# PIC32MX174F256B device description
Architecture: MIPS; Family: PIC32MX; Series: PIC32MX
Registers are 32-bit, read-write, no defined reset value unless marked. A register's access mark holds for its fields unless they carry their own. Offsets are from the block's base; [hi:lo] are bit positions; {n}, {i} and the like mark numbered series; 'fields as' and 'values as' point back to an identical list.

## OSC
Instances: OSC 0x1f80f000 in periph1
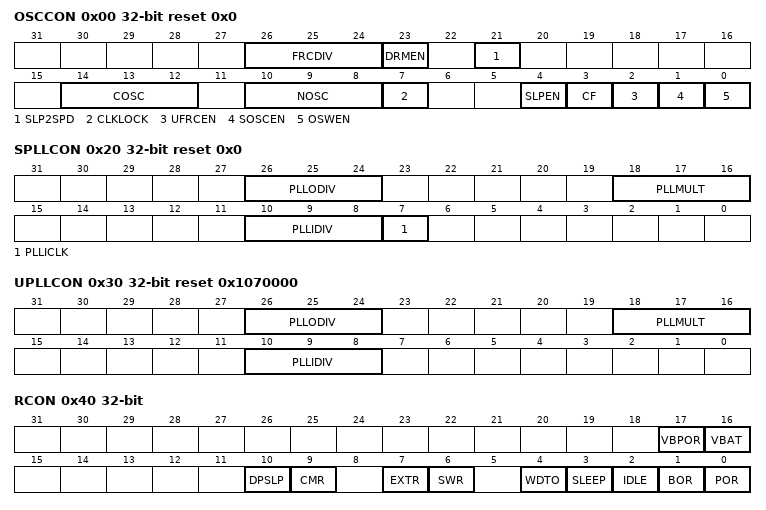
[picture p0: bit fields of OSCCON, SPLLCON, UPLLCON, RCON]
0x00 OSCCON reset 0x0 — Oscillator Control Register
  [26:24] FRCDIV — Internal Fast RC Oscillator Clock Divider bits
    7=DIV_256 (FRC divided by 256); 6=DIV_64 (FRC divided by 64); 5=DIV_32 (FRC divided by 32); 4=DIV_16 (FRC divided by 16); 3=DIV_8 (FRC divided by 8); 2=DIV_4 (FRC divided by 4); 1=DIV_2 (FRC divided by 2); 0=DIV_1 (FRC divided by 1 (default setting))
  [23] DRMEN — Dream Mode Enable bit
    1=ENABLE (Dream mode is enabled); 0=DISABLE (Dream mode is disabled)
  [21] SLP2SPD — Sleep Two-speed Start-up Control bit
    1=FRC (Use FRC as SYSCLK until the selected clock is ready); 0=DIRECT (Use the selected clock directly)
  [14:12] COSC — Current Oscillator Selection bits
    5=LPRC (Internal Low-Power RC (LPRC) Oscillator); 4=SOSC (Secondary Oscillator (SOSC)); 2=POSC (Primary Oscillator (POSC) (HS or EC)); 1=SPLL (System PLL (SPLL)); 0=FRC (Internal Fast RC (FRC) Oscillator divided by FRCDIV bits (FRCDIV))
  [10:8] NOSC — New Oscillator Selection bits
    values as COSC
  [7] CLKLOCK — Clock Selection Lock Enable bit
    1=ON (Clock and PLL selections are locked); 0=OFF (Clock and PLL selections are not locked and may be modified)
  [4] SLPEN — Sleep Mode Enable bit
    1=ENABLE (Device will enter Sleep mode when a WAIT instruction is executed); 0=DISABLE (Device will enter Idle mode when a WAIT instruction is executed)
  [3] CF — Clock Fail Detect bit
    1=DET (FSCM has detected a clock failure); 0=NO_DET (No clock failure has been detected)
  [2] UFRCEN — USB FRC Clock Enable bit
    1=FRC_EN (Enable FRC as the USB clock source); 0=FRC_DIS (Use the Primary Oscillator or UPLL as the USB clock source)
  [1] SOSCEN — Secondary Oscillator Enable bit
    1=ON (Enable Secondary Oscillator); 0=OFF (Disable Secondary Oscillator)
  [0] OSWEN — Oscillator Switch Enable bit
    1=ON (Initiate an oscillator switch to selection specified by NOSC bits); 0=OFF (Oscillator switch is complete)
0x10 OSCTUN reset 0x0 — FRC Tuning Register
  [5:0] TUN — FRC Oscillator Tuning bits
    32=FREQ_MIN (Center frequency -2%); 0=FREQ_CTR (Center frequency; Oscillator runs at nominal frequency (8 MHz)); 31=FREQ_MAX (Center frequency +2%)
0x20 SPLLCON reset 0x0 — System PLL Control Register
  [26:24] PLLODIV — System PLL Output Clock Divider bits
    7=DIV_256 (PLL Divide by 256); 6=DIV_64 (PLL Divide by 64); 5=DIV_32 (PLL Divide by 32); 4=DIV_16 (PLL Divide by 16); 3=DIV_8 (PLL Divide by 8); 2=DIV_4 (PLL Divide by 4); 1=DIV_2 (PLL Divide by 2); 0=DIV_1 (PLL Divide by 1)
  [18:16] PLLMULT — System PLL Multiplier bits
    7=MUL_24 (Multiply by 24); {v}=MUL_{v+15} (Multiply by {v+15}) (v=0..6)
  [10:8] PLLIDIV — System PLL Input Clock Divider bits
    7=DIV_12 (Divide by 12); 6=DIV_10 (Divide by 10); {v}=DIV_{v+1} (Divide by {v+1}) (v=0..5)
  [7] PLLICLK — System PLL Input Clock Source bit
    1=PLL_FRC (FRC is selected as the input to the System PLL); 0=PLL_POSC (POSC is selected as the input to the System PLL)
0x30 UPLLCON reset 0x1070000 — USB PLL Control Register
  [26:24] PLLODIV — USB PLL Output Clock Divider bits
    values as SPLLCON.PLLODIV
  [18:16] PLLMULT — USB PLL Multiplier bits
    values as SPLLCON.PLLMULT
  [10:8] PLLIDIV — USB PLL Input Clock Divider bits
    values as SPLLCON.PLLIDIV
0x40 RCON — Peripheral Bus Clock Divisor Control Register
  [17] VBPOR — VBPOR Mode Flag bit
    1=POR (A VBAT domain POR has occurred); 0=NO_POR (A VBAT domain POR has not occurred)
  [16] VBAT — VBAT Mode Flag bit
  [10] DPSLP — Deep Sleep Mode Flag bit
    1=DSLP (Deep Sleep mode has occurred); 0=NO_DSLP (Deep Sleep mode has not occurred)
  [9] CMR — Configuration Mismatch Reset Flag bit
    1=MISMATCH (A Configuration Mismatch Reset has occurred); 0=NO_MISMATCH (A Configuration Mismatch Reset has not occurred)
  [7] EXTR — External Reset (MCLR) Pin Flag bit
    1=RESET (Master Clear (pin) Reset has occurred); 0=NO_RESET (Master Clear (pin) Reset has not occurred)
  [6] SWR — Software Reset Flag bit
    1=SW_RESET (Software Reset was executed); 0=NO_SW_RESET (Software Reset was not executed)
  [4] WDTO — Watchdog Timer Time-out Flag bit
    1=WDTO (WDT Time-out has occurred); 0=NO_WDTO (WDT Time-out has not occurred)
  [3] SLEEP — Wake From Sleep Flag bit
    1=SLEEP (Device was in Sleep mode); 0=NO_SLEEP (Device was not in Sleep mode)
  [2] IDLE — Wake From Idle Flag bit
    1=IDLE (Device was in Idle mode); 0=NO_IDLE (Device was not in Idle mode)
  [1] BOR — Brown-out Reset Flag bit
    1=BOR (Brown-out Reset has occurred); 0=NO_BOR (Brown-out Reset has not occurred)
  [0] POR — Power-on Reset Flag bit
    1=POR (Power-on Reset has occurred); 0=NO_POR (Power-on Reset has not occurred)
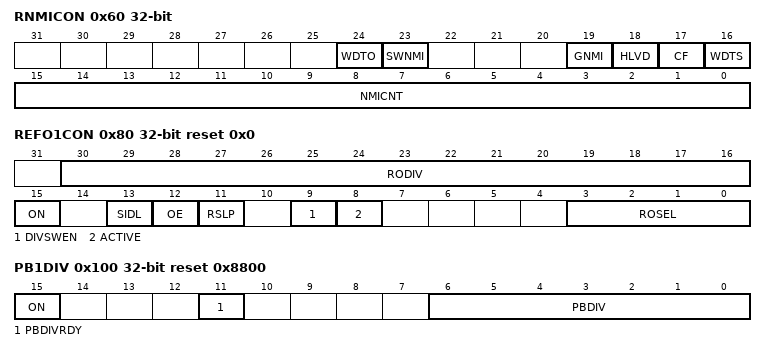
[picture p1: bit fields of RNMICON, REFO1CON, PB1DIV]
0x60 RNMICON — Non-maskable Interrupt (NMI) Control Register
  [24] WDTO — Watchdog Timer Time-Out Flag bit
    values as RCON.WDTO
  [23] SWNMI — Software NMI Trigger
  [19] GNMI — General NMI bit
  [18] HLVD — High/Low-Voltage Detect bit
  [17] CF — Clock Fail Detect bit
  [16] WDTS — Watchdog Timer Time-out in Sleep Mode Flag bit
  [15:0] NMICNT — NMI Reset Counter Value bits
0x70 PWRCON — Power Control Register
  [0] VREGS — Voltage Regulator Stand-by Enable bit
0x80 REFO1CON reset 0x0 — Reference Oscillator Control Register
  [30:16] RODIV — Reference Clock Divider Bits
    0x7FFF=DIV_65534 (REFO clock is Base clock frequency divided by 65534); 3=DIV_6 (REFO clock is Base clock frequency divided by 6); 2=DIV_4 (REFO clock is Base clock frequency divided by 4); 1=DIV_2 (REFO clock is Base clock frequency divided by 2); 0=NO_DIVIDER (No divider selected)
  [15] ON — Output Enable bit
    1=ENABLE (Reference Oscillator Module is enabled); 0=DISABLE (Reference Oscillator Module is disabled)
  [13] SIDL — Peripheral Stop in Idle Mode bit
    1=ENABLE (Discontinue module operation when device enters Idle mode); 0=DISABLE (Continue module operation in Idle mode)
  [12] OE — Reference Clock Output Enable bit
    1=ENABLE (Reference clock is driven out on REFCLKO pin); 0=DISABLE (Reference clock is not driven out on REFCLKO pin)
  [11] RSLP — Reference Oscillator Module Run in Sleep bit
    1=ENABLE (Reference Oscillator Module output continues to run in Sleep); 0=DISABLE (Reference Oscillator Module output is disabled in Sleep)
  [9] DIVSWEN — Divider Switch Enable bit
    1=IN_PROGRESS (Divider switch is in progress); 0=DONE (Divider switch is complete)
  [8] ACTIVE — Reference Clock Request Status bit
    1=ACTIVE (Reference clock request is active); 0=INACTIVE (Reference clock request is not active)
  [3:0] ROSEL — Reference Clock Source Select bits
    8=REFCLKI; 7=SPLL (System PLL output); 6=USBPLL (USB PLL output); 5=SOSC; 4=LPRC; 3=FRC; 2=POSC; 1=PBCLK; 0=SYSCLK
0x90 REFO1TRIM reset 0x0 — Reference Oscillator Trim Register
  [31:23] ROTRIM — Reference Oscillator Trim bits
    0x1ff=DIV_511_512 (511/512 divisor added to RODIV value); 0x1fe=DIV_510_512 (510/512 divisor added to RODIV value); 0x1fd=DIV_509_512 (509/512 divisor added to RODIV value); 0x1fc=DIV_508_512 (508/512 divisor added to RODIV value); 0x1fb=DIV_507_512 (507/512 divisor added to RODIV value); 0x1fa=DIV_506_512 (506/512 divisor added to RODIV value); 0x1f9=DIV_505_512 (505/512 divisor added to RODIV value); 0x1f8=DIV_504_512 (504/512 divisor added to RODIV value); 0x1f7=DIV_503_512 (503/512 divisor added to RODIV value); 0x1f6=DIV_502_512 (502/512 divisor added to RODIV value); 0x1f5=DIV_501_512 (501/512 divisor added to RODIV value); 0x1f4=DIV_500_512 (500/512 divisor added to RODIV value); 0x1f3=DIV_499_512 (499/512 divisor added to RODIV value); 0x1f2=DIV_498_512 (498/512 divisor added to RODIV value); 0x1f1=DIV_497_512 (497/512 divisor added to RODIV value); 0x1f0=DIV_496_512 (496/512 divisor added to RODIV value); 0x1ef=DIV_495_512 (495/512 divisor added to RODIV value); 0x1ee=DIV_494_512 (494/512 divisor added to RODIV value); 0x1ed=DIV_493_512 (493/512 divisor added to RODIV value); 0x1ec=DIV_492_512 (492/512 divisor added to RODIV value); 0x1eb=DIV_491_512 (491/512 divisor added to RODIV value); 0x1ea=DIV_490_512 (490/512 divisor added to RODIV value); 0x1e9=DIV_489_512 (489/512 divisor added to RODIV value); 0x1e8=DIV_488_512 (488/512 divisor added to RODIV value); 0x1e7=DIV_487_512 (487/512 divisor added to RODIV value); 0x1e6=DIV_486_512 (486/512 divisor added to RODIV value); 0x1e5=DIV_485_512 (485/512 divisor added to RODIV value); 0x1e4=DIV_484_512 (484/512 divisor added to RODIV value); 0x1e3=DIV_483_512 (483/512 divisor added to RODIV value); 0x1e2=DIV_482_512 (482/512 divisor added to RODIV value); 0x1e1=DIV_481_512 (481/512 divisor added to RODIV value); 0x1e0=DIV_480_512 (480/512 divisor added to RODIV value); 0x1df=DIV_479_512 (479/512 divisor added to RODIV value); 0x1de=DIV_478_512 (478/512 divisor added to RODIV value); 0x1dd=DIV_477_512 (477/512 divisor added to RODIV value); 0x1dc=DIV_476_512 (476/512 divisor added to RODIV value); 0x1db=DIV_475_512 (475/512 divisor added to RODIV value); 0x1da=DIV_474_512 (474/512 divisor added to RODIV value); 0x1d9=DIV_473_512 (473/512 divisor added to RODIV value); 0x1d8=DIV_472_512 (472/512 divisor added to RODIV value); 0x1d7=DIV_471_512 (471/512 divisor added to RODIV value); 0x1d6=DIV_470_512 (470/512 divisor added to RODIV value); 0x1d5=DIV_469_512 (469/512 divisor added to RODIV value); 0x1d4=DIV_468_512 (468/512 divisor added to RODIV value); 0x1d3=DIV_467_512 (467/512 divisor added to RODIV value); 0x1d2=DIV_466_512 (466/512 divisor added to RODIV value); 0x1d1=DIV_465_512 (465/512 divisor added to RODIV value); 0x1d0=DIV_464_512 (464/512 divisor added to RODIV value); 0x1cf=DIV_463_512 (463/512 divisor added to RODIV value); 0x1ce=DIV_462_512 (462/512 divisor added to RODIV value); 0x1cd=DIV_461_512 (461/512 divisor added to RODIV value); 0x1cc=DIV_460_512 (460/512 divisor added to RODIV value); 0x1cb=DIV_459_512 (459/512 divisor added to RODIV value); 0x1ca=DIV_458_512 (458/512 divisor added to RODIV value); 0x1c9=DIV_457_512 (457/512 divisor added to RODIV value); 0x1c8=DIV_456_512 (456/512 divisor added to RODIV value); 0x1c7=DIV_455_512 (455/512 divisor added to RODIV value); 0x1c6=DIV_454_512 (454/512 divisor added to RODIV value); 0x1c5=DIV_453_512 (453/512 divisor added to RODIV value); 0x1c4=DIV_452_512 (452/512 divisor added to RODIV value); 0x1c3=DIV_451_512 (451/512 divisor added to RODIV value); 0x1c2=DIV_450_512 (450/512 divisor added to RODIV value); 0x1c1=DIV_449_512 (449/512 divisor added to RODIV value); 0x1c0=DIV_448_512 (448/512 divisor added to RODIV value); 0x1bf=DIV_447_512 (447/512 divisor added to RODIV value); 0x1be=DIV_446_512 (446/512 divisor added to RODIV value); 0x1bd=DIV_445_512 (445/512 divisor added to RODIV value); 0x1bc=DIV_444_512 (444/512 divisor added to RODIV value); 0x1bb=DIV_443_512 (443/512 divisor added to RODIV value); 0x1ba=DIV_442_512 (442/512 divisor added to RODIV value); 0x1b9=DIV_441_512 (441/512 divisor added to RODIV value); 0x1b8=DIV_440_512 (440/512 divisor added to RODIV value); 0x1b7=DIV_439_512 (439/512 divisor added to RODIV value); 0x1b6=DIV_438_512 (438/512 divisor added to RODIV value); 0x1b5=DIV_437_512 (437/512 divisor added to RODIV value); 0x1b4=DIV_436_512 (436/512 divisor added to RODIV value); 0x1b3=DIV_435_512 (435/512 divisor added to RODIV value); 0x1b2=DIV_434_512 (434/512 divisor added to RODIV value); 0x1b1=DIV_433_512 (433/512 divisor added to RODIV value); 0x1b0=DIV_432_512 (432/512 divisor added to RODIV value); 0x1af=DIV_431_512 (431/512 divisor added to RODIV value); 0x1ae=DIV_430_512 (430/512 divisor added to RODIV value); 0x1ad=DIV_429_512 (429/512 divisor added to RODIV value); 0x1ac=DIV_428_512 (428/512 divisor added to RODIV value); 0x1ab=DIV_427_512 (427/512 divisor added to RODIV value); 0x1aa=DIV_426_512 (426/512 divisor added to RODIV value); 0x1a9=DIV_425_512 (425/512 divisor added to RODIV value); 0x1a8=DIV_424_512 (424/512 divisor added to RODIV value); 0x1a7=DIV_423_512 (423/512 divisor added to RODIV value); 0x1a6=DIV_422_512 (422/512 divisor added to RODIV value); 0x1a5=DIV_421_512 (421/512 divisor added to RODIV value); 0x1a4=DIV_420_512 (420/512 divisor added to RODIV value); 0x1a3=DIV_419_512 (419/512 divisor added to RODIV value); 0x1a2=DIV_418_512 (418/512 divisor added to RODIV value); 0x1a1=DIV_417_512 (417/512 divisor added to RODIV value); 0x1a0=DIV_416_512 (416/512 divisor added to RODIV value); 0x19f=DIV_415_512 (415/512 divisor added to RODIV value); 0x19e=DIV_414_512 (414/512 divisor added to RODIV value); 0x19d=DIV_413_512 (413/512 divisor added to RODIV value); 0x19c=DIV_412_512 (412/512 divisor added to RODIV value); 0x19b=DIV_411_512 (411/512 divisor added to RODIV value); 0x19a=DIV_410_512 (410/512 divisor added to RODIV value); 0x199=DIV_409_512 (409/512 divisor added to RODIV value); 0x198=DIV_408_512 (408/512 divisor added to RODIV value); 0x197=DIV_407_512 (407/512 divisor added to RODIV value); 0x196=DIV_406_512 (406/512 divisor added to RODIV value); 0x195=DIV_405_512 (405/512 divisor added to RODIV value); 0x194=DIV_404_512 (404/512 divisor added to RODIV value); 0x193=DIV_403_512 (403/512 divisor added to RODIV value); 0x192=DIV_402_512 (402/512 divisor added to RODIV value); 0x191=DIV_401_512 (401/512 divisor added to RODIV value); 0x190=DIV_400_512 (400/512 divisor added to RODIV value); 0x18f=DIV_399_512 (399/512 divisor added to RODIV value); 0x18e=DIV_398_512 (398/512 divisor added to RODIV value); 0x18d=DIV_397_512 (397/512 divisor added to RODIV value); 0x18c=DIV_396_512 (396/512 divisor added to RODIV value); 0x18b=DIV_395_512 (395/512 divisor added to RODIV value); 0x18a=DIV_394_512 (394/512 divisor added to RODIV value); 0x189=DIV_393_512 (393/512 divisor added to RODIV value); 0x188=DIV_392_512 (392/512 divisor added to RODIV value); 0x187=DIV_391_512 (391/512 divisor added to RODIV value); 0x186=DIV_390_512 (390/512 divisor added to RODIV value); 0x185=DIV_389_512 (389/512 divisor added to RODIV value); 0x184=DIV_388_512 (388/512 divisor added to RODIV value); 0x183=DIV_387_512 (387/512 divisor added to RODIV value); 0x182=DIV_386_512 (386/512 divisor added to RODIV value); 0x181=DIV_385_512 (385/512 divisor added to RODIV value); 0x180=DIV_384_512 (384/512 divisor added to RODIV value); 0x17f=DIV_383_512 (383/512 divisor added to RODIV value); 0x17e=DIV_382_512 (382/512 divisor added to RODIV value); 0x17d=DIV_381_512 (381/512 divisor added to RODIV value); 0x17c=DIV_380_512 (380/512 divisor added to RODIV value); 0x17b=DIV_379_512 (379/512 divisor added to RODIV value); 0x17a=DIV_378_512 (378/512 divisor added to RODIV value); 0x179=DIV_377_512 (377/512 divisor added to RODIV value); 0x178=DIV_376_512 (376/512 divisor added to RODIV value); 0x177=DIV_375_512 (375/512 divisor added to RODIV value); 0x176=DIV_374_512 (374/512 divisor added to RODIV value); 0x175=DIV_373_512 (373/512 divisor added to RODIV value); 0x174=DIV_372_512 (372/512 divisor added to RODIV value); 0x173=DIV_371_512 (371/512 divisor added to RODIV value); 0x172=DIV_370_512 (370/512 divisor added to RODIV value); 0x171=DIV_369_512 (369/512 divisor added to RODIV value); 0x170=DIV_368_512 (368/512 divisor added to RODIV value); 0x16f=DIV_367_512 (367/512 divisor added to RODIV value); 0x16e=DIV_366_512 (366/512 divisor added to RODIV value); 0x16d=DIV_365_512 (365/512 divisor added to RODIV value); 0x16c=DIV_364_512 (364/512 divisor added to RODIV value); 0x16b=DIV_363_512 (363/512 divisor added to RODIV value); 0x16a=DIV_362_512 (362/512 divisor added to RODIV value); 0x169=DIV_361_512 (361/512 divisor added to RODIV value); 0x168=DIV_360_512 (360/512 divisor added to RODIV value); 0x167=DIV_359_512 (359/512 divisor added to RODIV value); 0x166=DIV_358_512 (358/512 divisor added to RODIV value); 0x165=DIV_357_512 (357/512 divisor added to RODIV value); 0x164=DIV_356_512 (356/512 divisor added to RODIV value); 0x163=DIV_355_512 (355/512 divisor added to RODIV value); 0x162=DIV_354_512 (354/512 divisor added to RODIV value); 0x161=DIV_353_512 (353/512 divisor added to RODIV value); 0x160=DIV_352_512 (352/512 divisor added to RODIV value); 0x15f=DIV_351_512 (351/512 divisor added to RODIV value); 0x15e=DIV_350_512 (350/512 divisor added to RODIV value); 0x15d=DIV_349_512 (349/512 divisor added to RODIV value); 0x15c=DIV_348_512 (348/512 divisor added to RODIV value); 0x15b=DIV_347_512 (347/512 divisor added to RODIV value); 0x15a=DIV_346_512 (346/512 divisor added to RODIV value); 0x159=DIV_345_512 (345/512 divisor added to RODIV value); 0x158=DIV_344_512 (344/512 divisor added to RODIV value); 0x157=DIV_343_512 (343/512 divisor added to RODIV value); 0x156=DIV_342_512 (342/512 divisor added to RODIV value); 0x155=DIV_341_512 (341/512 divisor added to RODIV value); 0x154=DIV_340_512 (340/512 divisor added to RODIV value); 0x153=DIV_339_512 (339/512 divisor added to RODIV value); 0x152=DIV_338_512 (338/512 divisor added to RODIV value); 0x151=DIV_337_512 (337/512 divisor added to RODIV value); 0x150=DIV_336_512 (336/512 divisor added to RODIV value); 0x14f=DIV_335_512 (335/512 divisor added to RODIV value); 0x14e=DIV_334_512 (334/512 divisor added to RODIV value); 0x14d=DIV_333_512 (333/512 divisor added to RODIV value); 0x14c=DIV_332_512 (332/512 divisor added to RODIV value); 0x14b=DIV_331_512 (331/512 divisor added to RODIV value); 0x14a=DIV_330_512 (330/512 divisor added to RODIV value); 0x149=DIV_329_512 (329/512 divisor added to RODIV value); 0x148=DIV_328_512 (328/512 divisor added to RODIV value); 0x147=DIV_327_512 (327/512 divisor added to RODIV value); 0x146=DIV_326_512 (326/512 divisor added to RODIV value); 0x145=DIV_325_512 (325/512 divisor added to RODIV value); 0x144=DIV_324_512 (324/512 divisor added to RODIV value); 0x143=DIV_323_512 (323/512 divisor added to RODIV value); 0x142=DIV_322_512 (322/512 divisor added to RODIV value); 0x141=DIV_321_512 (321/512 divisor added to RODIV value); 0x140=DIV_320_512 (320/512 divisor added to RODIV value); 0x13f=DIV_319_512 (319/512 divisor added to RODIV value); 0x13e=DIV_318_512 (318/512 divisor added to RODIV value); 0x13d=DIV_317_512 (317/512 divisor added to RODIV value); 0x13c=DIV_316_512 (316/512 divisor added to RODIV value); 0x13b=DIV_315_512 (315/512 divisor added to RODIV value); 0x13a=DIV_314_512 (314/512 divisor added to RODIV value); 0x139=DIV_313_512 (313/512 divisor added to RODIV value); 0x138=DIV_312_512 (312/512 divisor added to RODIV value); 0x137=DIV_311_512 (311/512 divisor added to RODIV value); 0x136=DIV_310_512 (310/512 divisor added to RODIV value); 0x135=DIV_309_512 (309/512 divisor added to RODIV value); 0x134=DIV_308_512 (308/512 divisor added to RODIV value); 0x133=DIV_307_512 (307/512 divisor added to RODIV value); 0x132=DIV_306_512 (306/512 divisor added to RODIV value); 0x131=DIV_305_512 (305/512 divisor added to RODIV value); 0x130=DIV_304_512 (304/512 divisor added to RODIV value); 0x12f=DIV_303_512 (303/512 divisor added to RODIV value); 0x12e=DIV_302_512 (302/512 divisor added to RODIV value); 0x12d=DIV_301_512 (301/512 divisor added to RODIV value); 0x12c=DIV_300_512 (300/512 divisor added to RODIV value); 0x12b=DIV_299_512 (299/512 divisor added to RODIV value); 0x12a=DIV_298_512 (298/512 divisor added to RODIV value); 0x129=DIV_297_512 (297/512 divisor added to RODIV value); 0x128=DIV_296_512 (296/512 divisor added to RODIV value); 0x127=DIV_295_512 (295/512 divisor added to RODIV value); 0x126=DIV_294_512 (294/512 divisor added to RODIV value); 0x125=DIV_293_512 (293/512 divisor added to RODIV value); 0x124=DIV_292_512 (292/512 divisor added to RODIV value); 0x123=DIV_291_512 (291/512 divisor added to RODIV value); 0x122=DIV_290_512 (290/512 divisor added to RODIV value); 0x121=DIV_289_512 (289/512 divisor added to RODIV value); 0x120=DIV_288_512 (288/512 divisor added to RODIV value); 0x11f=DIV_287_512 (287/512 divisor added to RODIV value); 0x11e=DIV_286_512 (286/512 divisor added to RODIV value); 0x11d=DIV_285_512 (285/512 divisor added to RODIV value); 0x11c=DIV_284_512 (284/512 divisor added to RODIV value); 0x11b=DIV_283_512 (283/512 divisor added to RODIV value); 0x11a=DIV_282_512 (282/512 divisor added to RODIV value); 0x119=DIV_281_512 (281/512 divisor added to RODIV value); 0x118=DIV_280_512 (280/512 divisor added to RODIV value); 0x117=DIV_279_512 (279/512 divisor added to RODIV value); 0x116=DIV_278_512 (278/512 divisor added to RODIV value); 0x115=DIV_277_512 (277/512 divisor added to RODIV value); 0x114=DIV_276_512 (276/512 divisor added to RODIV value); 0x113=DIV_275_512 (275/512 divisor added to RODIV value); 0x112=DIV_274_512 (274/512 divisor added to RODIV value); 0x111=DIV_273_512 (273/512 divisor added to RODIV value); 0x110=DIV_272_512 (272/512 divisor added to RODIV value); 0x10f=DIV_271_512 (271/512 divisor added to RODIV value); 0x10e=DIV_270_512 (270/512 divisor added to RODIV value); 0x10d=DIV_269_512 (269/512 divisor added to RODIV value); 0x10c=DIV_268_512 (268/512 divisor added to RODIV value); 0x10b=DIV_267_512 (267/512 divisor added to RODIV value); 0x10a=DIV_266_512 (266/512 divisor added to RODIV value); 0x109=DIV_265_512 (265/512 divisor added to RODIV value); 0x108=DIV_264_512 (264/512 divisor added to RODIV value); 0x107=DIV_263_512 (263/512 divisor added to RODIV value); 0x106=DIV_262_512 (262/512 divisor added to RODIV value); 0x105=DIV_261_512 (261/512 divisor added to RODIV value); 0x104=DIV_260_512 (260/512 divisor added to RODIV value); 0x103=DIV_259_512 (259/512 divisor added to RODIV value); 0x102=DIV_258_512 (258/512 divisor added to RODIV value); 0x101=DIV_257_512 (257/512 divisor added to RODIV value); 0x100=DIV_256_512 (256/512 divisor added to RODIV value); {v}=DIV_{v}_512 ({v}/512 divisor added to RODIV value) (v=1..255); 0=DIV_0 (0 divisor added to RODIV value)
0x100 PB1DIV reset 0x8800 — Peripheral Bus Clock Divisor Control Register
  [15] ON — Output Enable bit
    1=ENABLED (PBCLK output clock is enabled); 0=DISABLED (PBCLK output clock is disabled)
  [11] PBDIVRDY — Peripheral Bus x Clock Divisor Ready bit
    1=READY (Clock divisor logic is not switching divisors and the PBDIV bits may be written); 0=NOT_READY (Clock divisor logic is currently switching values and the PBDIV bits cannot be written)
  [6:0] PBDIV — Peripheral Bus Clock Divisor Control bits
    {v}=DIV_{v+1} (PBCLK is SYSCLK divided by {v+1}) (v=0..127)
Value list RNMICON__WDTO: 1=WDTO (WDT time-out has occurred and caused a NMI); 0=NO_WDTO (WDT time-out has not occurred)
Value list RNMICON__SWNMI: 1=ENABLE (An NMI will be generated); 0=DISABLE (An NMI will not be generated)
Value list RNMICON__GNMI: 1=GNMI (A general NMI event has been detected or a user-initiated NMI event has occurred); 0=NO_GNMI (A general NMI event has not been detected)
Value list RNMICON__HLVD: 1=LOW_VOLTAGE (HLVD has detected a low-voltage condition and caused an NMI); 0=NO_LOW_VOLTAGE (HLVD has not detected a low-voltage condition)
Value list RNMICON__CF: 1=CLK_FAILURE (FSCM has detected clock failure and caused an NMI); 0=NO_CLK_FAILURE (FSCM has not detected clock failure)
Value list RNMICON__WDTS: 1=WDTO (WDT time-out has occurred during Sleep mode and caused a wake-up from sleep); 0=NO_WDTO (WDT time-out has not occurred during Sleep mode)
Value list RNMICON__NMICNT: 0xFFFF=SYSCLK_65535 (65535 SYSCLK cycles before a device Reset occurs); 0=NO_DELAY (No delay between NMI assertion and device Reset event)
Value list PWRCON__VREGS: 1=ACTIVE (Voltage regulator will remain active during Sleep); 0=STDBY (Voltage regulator will go to Stand-by mode during Sleep)

## Notices in the file
Copyright (c) 2019 Microchip Technology Inc.
SPDX-License-Identifier: Apache-2.0
Licensed under the Apache License, Version 2.0 (the "License");
you may not use this file except in compliance with the License.
You may obtain a copy of the License at
http://www.apache.org/licenses/LICENSE-2.0
Unless required by applicable law or agreed to in writing, software
distributed under the License is distributed on an "AS IS" BASIS,
WITHOUT WARRANTIES OR CONDITIONS OF ANY KIND, either express or implied.
See the License for the specific language governing permissions and
limitations under the License.
